# ZB32L030 register map
Vendor: ZBit.; Series: ZB32L03X; File version: 1.0
CPU: CM0+ r1p0, little endian, no MPU, no FPU, VTOR, 2 interrupt priority bits
Registers are 32-bit, read-write, reset 0x0 unless marked. A register's access mark holds for its fields unless they carry their own. Offsets are from the block's base; [hi:lo] are bit positions.

## RTC
Base 0x40003000
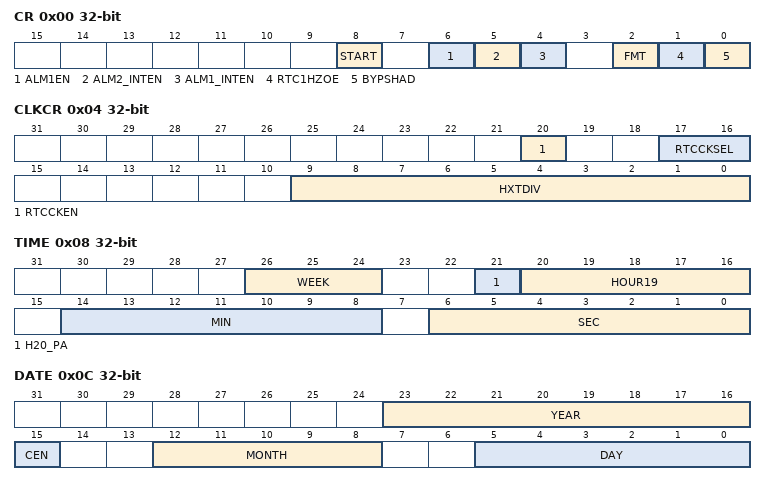
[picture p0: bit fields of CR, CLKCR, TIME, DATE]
0x00 CR
  [8] START — RTC start
  [6] ALM1EN — Alarm1 enable
  [5] ALM2_INTEN — Enable alarm2 interrupt
  [4] ALM1_INTEN — Enable alarm1 interrupt
  [2] FMT — Format
  [1] RTC1HZOE — Enable 1Hz
  [0] BYPSHAD — By pass
0x04 CLKCR
  [20] RTCCKEN — RTC clock enable
  [17:16] RTCCKSEL — RTC clock source select
  [9:0] HXTDIV — HXT div (F=F_HXT/(HXTDIV[9:0])
0x08 TIME
  [26:24] WEEK — Week counter
  [21] H20_PA — Hour mode (AM/PM)
  [20:16] HOUR19 — Hour counter
  [14:8] MIN — Minute counter
  [6:0] SEC — Second counter
0x0C DATE
  [23:16] YEAR — Year counter
  [15] CEN — Century counter (0: 20, 1: 21)
  [12:8] MONTH — Month counter
  [5:0] DAY — Day counter
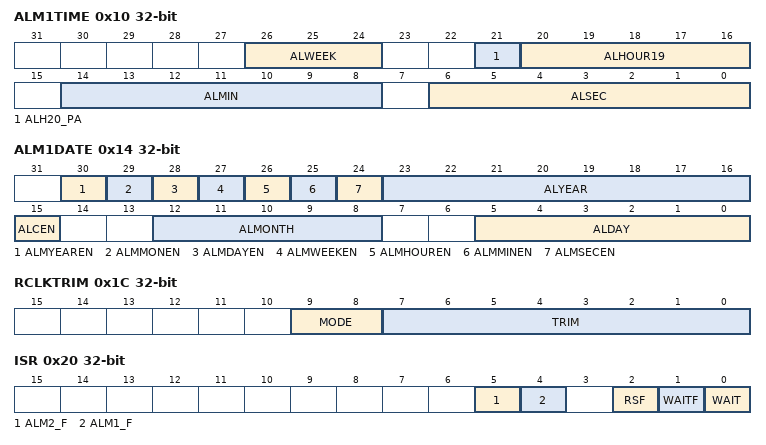
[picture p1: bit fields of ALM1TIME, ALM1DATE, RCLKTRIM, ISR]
0x10 ALM1TIME — ALM
  [26:24] ALWEEK — Alarm week configuration
  [21] ALH20_PA — Alarm hour configuration
  [20:16] ALHOUR19 — Alarm hour configuration
  [14:8] ALMIN — Alarm minute configuration
  [6:0] ALSEC — Alarm second configuration
0x14 ALM1DATE — ALM
  [30] ALMYEAREN — enable Alarm year configuration
  [29] ALMMONEN — enable Alarm month configuration
  [28] ALMDAYEN — enable Alarm day configuration
  [27] ALMWEEKEN — enable Alarm week configuration
  [26] ALMHOUREN — enable Alarm hour configuration
  [25] ALMMINEN — enable Alarm minute configuration
  [24] ALMSECEN — enable Alarm second configuration
  [23:16] ALYEAR — Alarm year configuration
  [15] ALCEN — Alarm century configuration
  [12:8] ALMONTH — Alarm month configuration
  [5:0] ALDAY — Alarm day configuration
0x18 ALM2PRD — ALM PR
  [3:0] ALM2PR_CNT — Alarm2 periodic configuration
    0=ALM2_OFF (Disable Alarm 2); 1=1_SEC (1 second); 2=500_MSEC (500 mseconds); 3=250_MSEC (250 msecond); 4=125_MSEC (125 msecond); 5=62_5_MSEC (62.5 msecond); 6=31_25_MSEC (31.25 msecond); 7=15_625_MSEC (15.625 msecond); 8=7_8125_MSEC (7.8125 msecond); 9=10_SEC (10 seconds); 10=30_SEC (30 seconds); 11=1_MIN (1 minute); 12=30_MIN (30 minute); 13=60_MIN (60 minute); 14=12_HOUR (12 hours); 15=24_HOUR (24 hours)
0x1C RCLKTRIM — RTC clock trim
  [9:8] MODE — clock mode
    0=60_SEC (60 seconds); 1=30_SEC (30 seconds); 2=15_SEC (15 seconds); 3=6_SEC (6 seconds)
  [7:0] TRIM — clock trim value (-128 ~ 127)
0x20 ISR — Init
  [5] ALM2_F ro — Alarm2 interrupt status
  [4] ALM1_F ro — Alarm1 interrupt status
  [2] RSF — sync flag
  [1] WAITF
  [0] WAIT
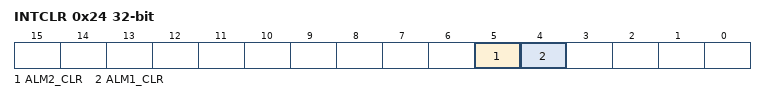
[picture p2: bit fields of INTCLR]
0x24 INTCLR — Status Clean
  [5] ALM2_CLR wo — Alarm2 clear status
  [4] ALM1_CLR wo — Alarm1 clear status
0x28 WPR — RTC
  [7:0] WPR wo — write protection

## CLKTRIM
Base 0x40003400
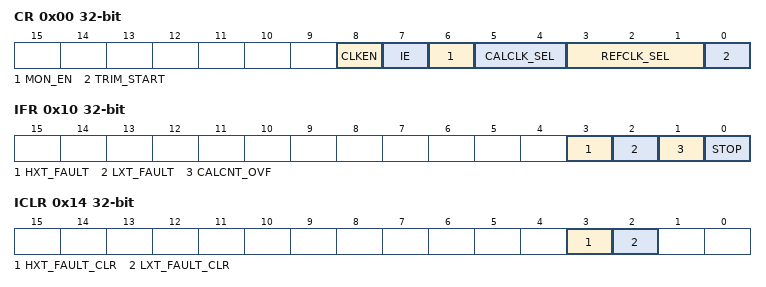
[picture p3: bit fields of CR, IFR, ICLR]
0x00 CR — Config Register
  [8] CLKEN — enable clktrim
  [7] IE — interrupt enable
  [6] MON_EN
  [5:4] CALCLK_SEL
    0=HIRC (use HIRC); 1=HXT (use HXT); 2=SIRC (use SIRC); 3=LXT (use LXT)
  [3:1] REFCLK_SEL
    0=HIRC (use HIRC); 1=HXT (use HXT); 2=SIRC (use SIRC); 3=LXT (use LXT); 4=HXT_BYPASS (use HXT-Bypass)
  [0] TRIM_START
0x04 REFCON reset 0xFFFFFFFF — Reference Count Orignal Config Register
  [31:0] RCNTVAL — Ref. count default value
0x08 REFCNT reset 0xFFFFFFFF — Reference Count Register
  [31:0] REFCNT ro — Reference Count
0x0C CALCNT — Calibration count register
  [31:0] CALCNT ro — Calibration count
0x10 IFR — Interrupt Flag Register
  [3] HXT_FAULT ro
  [2] LXT_FAULT ro
  [1] CALCNT_OVF ro — CALCNT overflow
  [0] STOP ro
0x14 ICLR — Interrupt Flag Clear Register
  [3] HXT_FAULT_CLR wo — HXT fault clear
  [2] LXT_FAULT_CLR wo — LXT fault clear
0x18 CALCON — Count Overtime Control Register
  [15:0] CALOVCNT — Calibration overflow count

## OWIRE — One Wire
Base 0x40003800
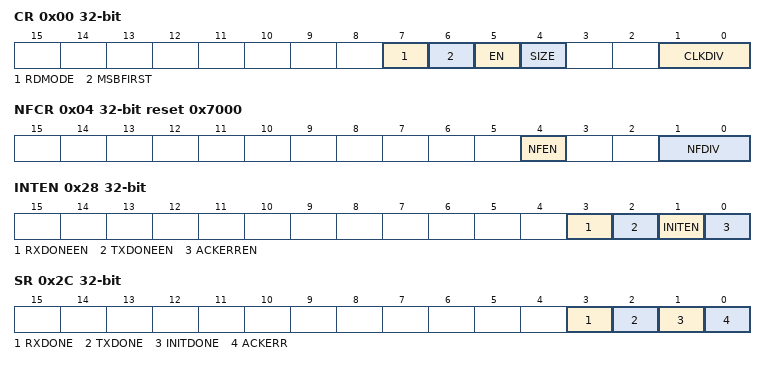
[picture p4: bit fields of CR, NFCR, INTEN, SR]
0x00 CR — 1-Wire Model Control Register
  [7] RDMODE — Read mode
  [6] MSBFIRST
  [5] EN — 1-wire enable
  [4] SIZE — data size
  [1:0] CLKDIV — Clock Prescale
    0=DIV1 (Prescale 1); 1=DIV2 (Prescale 2); 2=DIV4 (Prescale 4); 3=DIV16 (Prescale 16)
0x04 NFCR reset 0x7000 — 1-Wire Input EndPoint Control
  [4] NFEN — NF enable
  [1:0] NFDIV — NF division
    0=DIV1 (Prescale 1); 1=DIV2 (Prescale 2); 2=DIV4 (Prescale 4); 3=DIV8 (Prescale 8)
0x08 RSTCNT — 1-Wire Master Reset Pulse Count register
  [15:0] RSTCNT — Reset count
0x0C PRESCNT — 1-Wire Device Presence Pulse Count Register
  [12:0] PRESCNT — Presence count
0x10 BITRATECNT — 1-Wire Bit Rate Design Count
  [11:0] BITRATECNT — Bit rate count
0x14 DRVCNT — 1-Wire Main Read/Write Pull0
  [8:0] DRVCNT — Driving time
0x18 RDSMPCNT — 1-Wire Main Read Sample Time Setting
  [8:0] RDSMPCNT — Read Sample Time
0x1C RECCNT — 1-Wire Recover Time Count
  [10:0] RECCNT — Recover Time
0x20 DATA — 1_Wire Data Register
  [7:0] DATA
0x24 CMD — 1_Wire Bus Operate Command Register
  [1:0] CMD — command
0x28 INTEN — 1-Wire Interrupt Enable Register
  [3] RXDONEEN — Rx done interrut enable
  [2] TXDONEEN — Tx done interrupt enable
  [1] INITEN — Initialized interrupt enable
  [0] ACKERREN — enable ack-error interrupt
0x2C SR — 1-Wire Status Register
  [3] RXDONE ro — Rx done flag
  [2] TXDONE ro — Tx done flag
  [1] INITDONE ro — Initializing done flag
  [0] ACKERR ro — ACK error flag
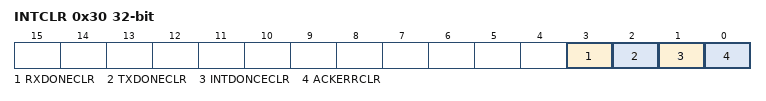
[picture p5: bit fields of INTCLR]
0x30 INTCLR — 1-Wire Interrupt Status Clean Register
  [3] RXDONECLR wo — Rx done clear
  [2] TXDONECLR wo — Tx done clear
  [1] INTDONCECLR wo — Initializing done clear
  [0] ACKERRCLR wo — ACK error clear
